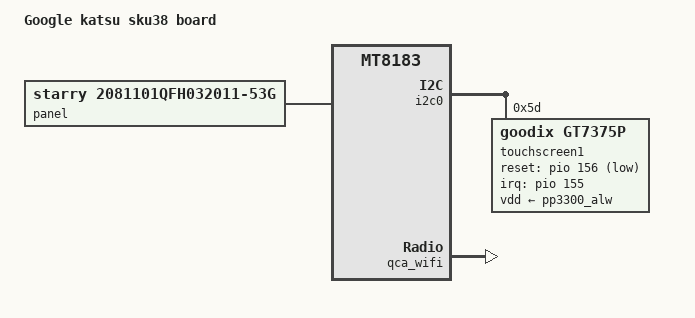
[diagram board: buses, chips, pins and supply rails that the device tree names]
// SPDX-License-Identifier: (GPL-2.0 OR MIT)
/*
 * Copyright 2023 Google LLC
 */

/dts-v1/;
#include "mt8183-kukui-kakadu.dtsi"
#include "mt8183-kukui-audio-rt1015p.dtsi"

/ {
	model = "Google katsu sku38 board";
	chassis-type = "tablet";
	compatible = "google,katsu-sku38", "google,katsu", "mediatek,mt8183";
};

&i2c0 {
	touchscreen1: touchscreen@5d {
		compatible = "goodix,gt7375p";
		reg = <0x5d>;
		pinctrl-names = "default";
		pinctrl-0 = <&open_touch>;

		interrupts-extended = <&pio 155 IRQ_TYPE_LEVEL_LOW>;

		reset-gpios = <&pio 156 GPIO_ACTIVE_LOW>;
		vdd-supply = <&pp3300_alw>;
	};
};

&panel {
	compatible = "starry,2081101qfh032011-53g";
};

&qca_wifi {
	qcom,ath10k-calibration-variant = "GO_KATSU";
};

&sound {
	compatible = "mediatek,mt8183_mt6358_ts3a227_rt1015p";
};
